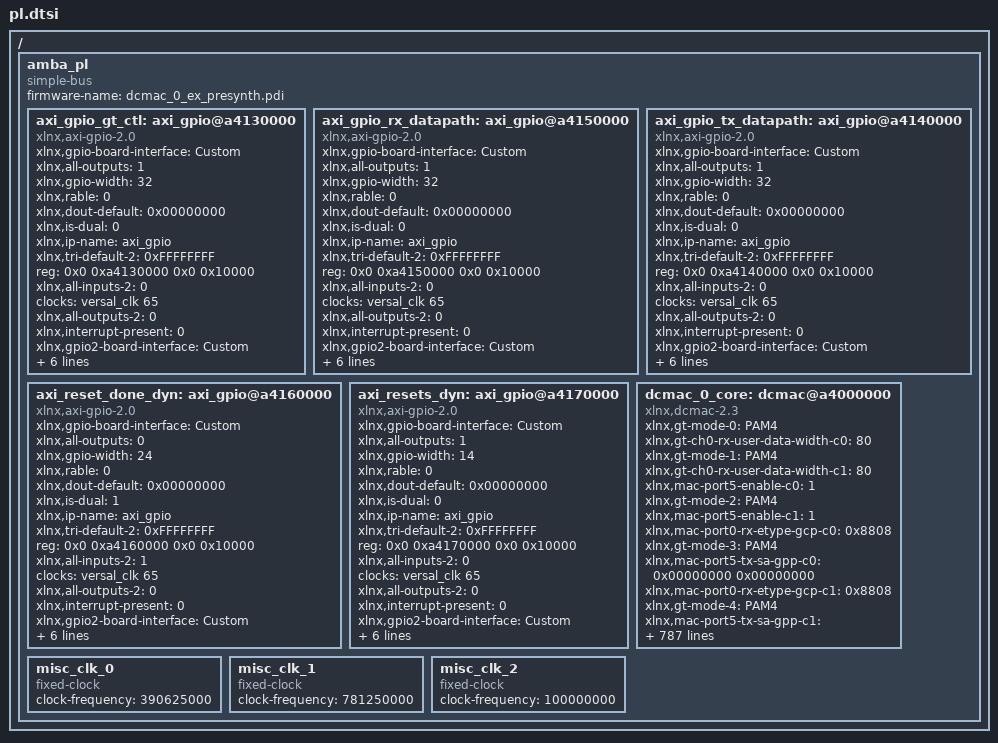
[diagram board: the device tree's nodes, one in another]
/ {
	amba_pl: amba_pl {
		ranges;
		compatible = "simple-bus";
		#address-cells = <2>;
		#size-cells = <2>;
		firmware-name = "dcmac_0_ex_presynth.pdi";
		axi_gpio_gt_ctl: axi_gpio@a4130000 {
			xlnx,gpio-board-interface = "Custom";
			compatible = "xlnx,axi-gpio-2.0" , "xlnx,xps-gpio-1.00.a";
			xlnx,all-outputs = <1>;
			xlnx,gpio-width = <32>;
			xlnx,rable = <0>;
			xlnx,dout-default = <0x00000000>;
			xlnx,is-dual = <0>;
			xlnx,ip-name = "axi_gpio";
			xlnx,tri-default-2 = <0xFFFFFFFF>;
			reg = <0x0 0xa4130000 0x0 0x10000>;
			xlnx,all-inputs-2 = <0>;
			clocks = <&versal_clk 65>;
			xlnx,all-outputs-2 = <0>;
			xlnx,interrupt-present = <0>;
			xlnx,gpio2-board-interface = "Custom";
			xlnx,edk-iptype = "PERIPHERAL";
			xlnx,dout-default-2 = <0x00000000>;
			xlnx,gpio2-width = <32>;
			status = "okay";
			clock-names = "s_axi_aclk";
			xlnx,tri-default = <0xFFFFFFFF>;
			xlnx,name = "axi_gpio_gt_ctl";
			xlnx,all-inputs = <0>;
		};
		axi_gpio_rx_datapath: axi_gpio@a4150000 {
			xlnx,gpio-board-interface = "Custom";
			compatible = "xlnx,axi-gpio-2.0" , "xlnx,xps-gpio-1.00.a";
			xlnx,all-outputs = <1>;
			xlnx,gpio-width = <32>;
			xlnx,rable = <0>;
			xlnx,dout-default = <0x00000000>;
			xlnx,is-dual = <0>;
			xlnx,ip-name = "axi_gpio";
			xlnx,tri-default-2 = <0xFFFFFFFF>;
			reg = <0x0 0xa4150000 0x0 0x10000>;
			xlnx,all-inputs-2 = <0>;
			clocks = <&versal_clk 65>;
			xlnx,all-outputs-2 = <0>;
			xlnx,interrupt-present = <0>;
			xlnx,gpio2-board-interface = "Custom";
			xlnx,edk-iptype = "PERIPHERAL";
			xlnx,dout-default-2 = <0x00000000>;
			xlnx,gpio2-width = <32>;
			status = "okay";
			clock-names = "s_axi_aclk";
			xlnx,tri-default = <0xFFFFFFFF>;
			xlnx,name = "axi_gpio_rx_datapath";
			xlnx,all-inputs = <0>;
		};
		axi_gpio_tx_datapath: axi_gpio@a4140000 {
			xlnx,gpio-board-interface = "Custom";
			compatible = "xlnx,axi-gpio-2.0" , "xlnx,xps-gpio-1.00.a";
			xlnx,all-outputs = <1>;
			xlnx,gpio-width = <32>;
			xlnx,rable = <0>;
			xlnx,dout-default = <0x00000000>;
			xlnx,is-dual = <0>;
			xlnx,ip-name = "axi_gpio";
			xlnx,tri-default-2 = <0xFFFFFFFF>;
			reg = <0x0 0xa4140000 0x0 0x10000>;
			xlnx,all-inputs-2 = <0>;
			clocks = <&versal_clk 65>;
			xlnx,all-outputs-2 = <0>;
			xlnx,interrupt-present = <0>;
			xlnx,gpio2-board-interface = "Custom";
			xlnx,edk-iptype = "PERIPHERAL";
			xlnx,dout-default-2 = <0x00000000>;
			xlnx,gpio2-width = <32>;
			status = "okay";
			clock-names = "s_axi_aclk";
			xlnx,tri-default = <0xFFFFFFFF>;
			xlnx,name = "axi_gpio_tx_datapath";
			xlnx,all-inputs = <0>;
		};
		axi_reset_done_dyn: axi_gpio@a4160000 {
			xlnx,gpio-board-interface = "Custom";
			compatible = "xlnx,axi-gpio-2.0" , "xlnx,xps-gpio-1.00.a";
			xlnx,all-outputs = <0>;
			xlnx,gpio-width = <24>;
			xlnx,rable = <0>;
			xlnx,dout-default = <0x00000000>;
			xlnx,is-dual = <1>;
			xlnx,ip-name = "axi_gpio";
			xlnx,tri-default-2 = <0xFFFFFFFF>;
			reg = <0x0 0xa4160000 0x0 0x10000>;
			xlnx,all-inputs-2 = <1>;
			clocks = <&versal_clk 65>;
			xlnx,all-outputs-2 = <0>;
			xlnx,interrupt-present = <0>;
			xlnx,gpio2-board-interface = "Custom";
			xlnx,edk-iptype = "PERIPHERAL";
			xlnx,dout-default-2 = <0x00000000>;
			xlnx,gpio2-width = <24>;
			status = "okay";
			clock-names = "s_axi_aclk";
			xlnx,tri-default = <0xFFFFFFFF>;
			xlnx,name = "axi_reset_done_dyn";
			xlnx,all-inputs = <1>;
		};
		axi_resets_dyn: axi_gpio@a4170000 {
			xlnx,gpio-board-interface = "Custom";
			compatible = "xlnx,axi-gpio-2.0" , "xlnx,xps-gpio-1.00.a";
			xlnx,all-outputs = <1>;
			xlnx,gpio-width = <14>;
			xlnx,rable = <0>;
			xlnx,dout-default = <0x00000000>;
			xlnx,is-dual = <0>;
			xlnx,ip-name = "axi_gpio";
			xlnx,tri-default-2 = <0xFFFFFFFF>;
			reg = <0x0 0xa4170000 0x0 0x10000>;
			xlnx,all-inputs-2 = <0>;
			clocks = <&versal_clk 65>;
			xlnx,all-outputs-2 = <0>;
			xlnx,interrupt-present = <0>;
			xlnx,gpio2-board-interface = "Custom";
			xlnx,edk-iptype = "PERIPHERAL";
			xlnx,dout-default-2 = <0x00000000>;
			xlnx,gpio2-width = <32>;
			status = "okay";
			clock-names = "s_axi_aclk";
			xlnx,tri-default = <0xFFFFFFFF>;
			xlnx,name = "axi_resets_dyn";
			xlnx,all-inputs = <0>;
		};
		dcmac_0_core: dcmac@a4000000 {
			xlnx,gt-mode-0 = "PAM4";
			xlnx,gt-ch0-rx-user-data-width-c0 = <80>;
			xlnx,gt-mode-1 = "PAM4";
			xlnx,gt-ch0-rx-user-data-width-c1 = <80>;
			xlnx,mac-port5-enable-c0 = <1>;
			xlnx,gt-mode-2 = "PAM4";
			xlnx,mac-port5-enable-c1 = <1>;
			xlnx,mac-port0-rx-etype-gcp-c0 = <0x8808>;
			xlnx,gt-mode-3 = "PAM4";
			xlnx,mac-port5-tx-sa-gpp-c0 = <0x00000000 0x00000000>;
			xlnx,mac-port0-rx-etype-gcp-c1 = <0x8808>;
			xlnx,gt-mode-4 = "PAM4";
			xlnx,mac-port5-tx-sa-gpp-c1 = <0x00000000 0x00000000>;
			xlnx,mac-port2-rx-etype-gcp-c0 = <0x8808>;
			xlnx,mac-port2-rx-etype-gcp-c1 = <0x8808>;
			xlnx,mac-port1-rx-flow-c0 = <0>;
			reg = <0x0 0xa4000000 0x0 0x100000>;
			xlnx,gt-ch0-tx-int-data-width-c0 = <80>;
			xlnx,mac-port4-rx-etype-gcp-c0 = <0x8808>;
			xlnx,mac-port3-tx-insert-c0 = <1>;
			xlnx,mac-port1-rx-flow-c1 = <0>;
			xlnx,gt-ch0-tx-int-data-width-c1 = <80>;
			xlnx,mac-port4-rx-etype-gcp-c1 = <0x8808>;
			xlnx,mac-port3-tx-insert-c1 = <1>;
			xlnx,mac-port2-tx-ethertype-ppp-c0 = <0x8808>;
			xlnx,mac-port2-tx-ethertype-ppp-c1 = <0x8808>;
			xlnx,gt-ch1-txprogdiv-freq-val-c0 = <0x266ac338>;
			xlnx,gt-ch1-txprogdiv-freq-val-c1 = <0x266ac338>;
			xlnx,port5-1588v2-operation-mode-c0 = "No , operation";
			xlnx,gt-ch2-rx-data-decoding-c0 = "RAW";
			xlnx,port5-1588v2-operation-mode-c1 = "No , operation";
			xlnx,oth-pcs-port0-config3-c0 = "N/A";
			xlnx,mac-port4-tx-sa-ppp-c0 = <0x00000000 0x00000000>;
			xlnx,diffclk-board-interface = "Custom";
			xlnx,gt-ch2-rx-data-decoding-c1 = "RAW";
			xlnx,oth-pcs-port0-config3-c1 = "100CAUI-4";
			xlnx,mac-port4-tx-sa-ppp-c1 = <0x00000000 0x00000000>;
			xlnx,mac-port4-rx-pause-da-ucast-c0 = <0x00000000 0x00000000>;
			xlnx,mac-port4-rx-pause-da-ucast-c1 = <0x00000000 0x00000000>;
			xlnx,mac-port0-rx-opcode-min-pcp-c0 = <0x0000>;
			xlnx,mac-port0-rx-opcode-min-pcp-c1 = <0x0000>;
			xlnx,mac-port3-preemption-c0 = <0>;
			xlnx,mac-port2-rx-opcode-max-pcp-c0 = <0xFFFF>;
			xlnx,mac-port3-preemption-c1 = <0>;
			xlnx,mac-port2-rx-opcode-max-pcp-c1 = <0xFFFF>;
			xlnx,mac-port0-tx-opcode-ppp-c0 = <0x0101>;
			xlnx,gt-ch0-tx-pll-type-c0 = "LCPLL";
			xlnx,oth-pcs-port2-config4-c0 = "N/A";
			xlnx,mac-port2-tx-ethertype-gpp-c0 = <0x8808>;
			xlnx,mac-port0-tx-opcode-ppp-c1 = <0x0101>;
			xlnx,gt-ch0-tx-pll-type-c1 = "LCPLL";
			xlnx,oth-pcs-port2-config4-c1 = "100CAUI-4";
			xlnx,mac-port4-config-c0 = "Disabled";
			xlnx,mac-port2-tx-ethertype-gpp-c1 = <0x8808>;
			xlnx,num-gt-channels-port0 = <2>;
			xlnx,mac-port4-config-c1 = "N/A";
			xlnx,num-gt-channels-port1 = <2>;
			xlnx,num-gt-channels-port2 = <2>;
			xlnx,mac-port4-tx-sa-gpp-c0 = <0x00000000 0x00000000>;
			xlnx,num-gt-channels-port3 = <2>;
			xlnx,mac-port4-tx-sa-gpp-c1 = <0x00000000 0x00000000>;
			xlnx,num-gt-channels-port4 = <0>;
			xlnx,mac-port3-rx-pause-da-mcast-c0 = <0x00000180 0xC2000001>;
			xlnx,port0-1588v2-operation-mode-c0 = "No , operation";
			xlnx,num-gt-channels-port5 = <0>;
			xlnx,mac-port3-rx-pause-da-mcast-c1 = <0x00000180 0xC2000001>;
			xlnx,mac-port2-tx-insert-c0 = <1>;
			xlnx,port2-1588v2-clocking-c0 = "Ordinary/Boundary , Clock";
			xlnx,port0-1588v2-operation-mode-c1 = "No , operation";
			xlnx,mac-port2-tx-insert-c1 = <1>;
			xlnx,mac-port2-rx-flow-c0 = <0>;
			xlnx,mac-port0-rx-opcode-min-gcp-c0 = <0x0000>;
			xlnx,name = "dcmac_0_core";
			xlnx,gt-ch2-rx-outclk-source-c0 = "RXPROGDIVCLK";
			xlnx,port2-1588v2-clocking-c1 = "Ordinary/Boundary , Clock";
			xlnx,mac-port2-rx-flow-c1 = <0>;
			xlnx,mac-port0-rx-opcode-min-gcp-c1 = <0x0000>;
			xlnx,gt-ch2-rx-outclk-source-c1 = "RXPROGDIVCLK";
			xlnx,gt-ch2-txprogdiv-freq-source-c0 = "LCPLL";
			xlnx,mac-port0-rx-etype-ppp-c0 = <0x8808>;
			xlnx,gt-ch2-txprogdiv-freq-source-c1 = "LCPLL";
			xlnx,mac-port0-rx-etype-ppp-c1 = <0x8808>;
			xlnx,mac-port3-tx-sa-ppp-c0 = <0x00000000 0x00000000>;
			xlnx,mac-port2-rx-opcode-max-gcp-c0 = <0xFFFF>;
			xlnx,mac-port2-rx-etype-ppp-c0 = <0x8808>;
			xlnx,gt-mode-dyn = "PAM4";
			xlnx,gt-drp-clk-c0 = <100>;
			xlnx,mac-port3-tx-sa-ppp-c1 = <0x00000000 0x00000000>;
			xlnx,mac-port2-rx-opcode-max-gcp-c1 = <0xFFFF>;
			xlnx,mac-port2-rx-etype-ppp-c1 = <0x8808>;
			xlnx,gt-drp-clk-c1 = <100>;
			xlnx,gt-ch2-tx-user-data-width-c0 = <80>;
			xlnx,oth-pcs-port1-config3-c0 = "N/A";
			xlnx,mac-port4-rx-etype-ppp-c0 = <0x8808>;
			xlnx,mac-port0-tx-opcode-gpp-c0 = <0x0001>;
			xlnx,gt-ch2-tx-user-data-width-c1 = <80>;
			xlnx,oth-pcs-port1-config3-c1 = "100CAUI-4";
			xlnx,mac-port5-tx-da-ppp-c0 = <0x00000180 0xC2000001>;
			xlnx,mac-port4-rx-etype-ppp-c1 = <0x8808>;
			xlnx,mac-port0-tx-opcode-gpp-c1 = <0x0001>;
			xlnx,mac-port5-tx-da-ppp-c1 = <0x00000180 0xC2000001>;
			xlnx,gt-ch3-txprogdiv-freq-enable-c0;
			xlnx,mac-port2-tx-opcode-ppp-c0 = <0x0101>;
			xlnx,gt-ch3-txprogdiv-freq-enable-c1;
			xlnx,mac-port5-rx-pause-sa-c0 = <0x00000000 0x00000000>;
			xlnx,mac-port3-tx-ethertype-ppp-c0 = <0x8808>;
			xlnx,mac-port2-tx-opcode-ppp-c1 = <0x0101>;
			xlnx,port5-1588v2-clocking-c0 = "Ordinary/Boundary , Clock";
			xlnx,mac-port5-rx-pause-sa-c1 = <0x00000000 0x00000000>;
			xlnx,mac-port3-tx-ethertype-ppp-c1 = <0x8808>;
			xlnx,gt-ch1-rx-buffer-mode-c0 = <1>;
			xlnx,port5-1588v2-clocking-c1 = "Ordinary/Boundary , Clock";
			xlnx,gt-ch1-rx-buffer-mode-c1 = <1>;
			xlnx,gt-ch1-tx-buffer-mode-c0 = <1>;
			xlnx,gt-ch3-rx-data-decoding-c0 = "RAW";
			clock-names = "rx_axi_clk" , "rx_core_clk" , "rx_flexif_clk" , "rx_macif_clk" , "s_axi_aclk" , "ts_clk" , "tx_axi_clk" , "tx_core_clk" , "tx_flexif_clk" , "tx_macif_clk";
			xlnx,mac-port1-rx-opcode-ppp-c0 = <0x0101>;
			xlnx,mac-port0-enable-c0 = <1>;
			xlnx,gt-ch1-tx-buffer-mode-c1 = <1>;
			xlnx,gt-ch3-rx-data-decoding-c1 = "RAW";
			xlnx,mac-port1-rx-opcode-ppp-c1 = <0x0101>;
			xlnx,mac-port0-enable-c1 = <1>;
			xlnx,gt-ch2-rxprogdiv-freq-source-c0 = "LCPLL";
			xlnx,gtm-group-select2-c0 = "GTM_DUAL_X0Y0";
			xlnx,gt-ch1-tx-int-data-width-c0 = <80>;
			xlnx,gt-ch2-rxprogdiv-freq-source-c1 = "LCPLL";
			xlnx,oth-pcs-port3-config4-c0 = "N/A";
			xlnx,mac-port0-rx-etype-gpp-c0 = <0x8808>;
			xlnx,gtm-group-select2-c1 = "GTM_DUAL_X0Y0";
			xlnx,ethernet-board-interface = "Custom";
			xlnx,gt-ch1-tx-int-data-width-c1 = <80>;
			xlnx,oth-pcs-port3-config4-c1 = "100CAUI-4";
			xlnx,mac-port0-rx-etype-gpp-c1 = <0x8808>;
			xlnx,mac-port3-tx-sa-gpp-c0 = <0x00000000 0x00000000>;
			xlnx,mac-port2-rx-etype-gpp-c0 = <0x8808>;
			xlnx,oth-pcs-port0-config2-c0 = "N/A";
			xlnx,mac-port3-tx-sa-gpp-c1 = <0x00000000 0x00000000>;
			xlnx,mac-port2-rx-etype-gpp-c1 = <0x8808>;
			xlnx,mac-port2-enable-time-stamping-c0 = <0>;
			xlnx,oth-pcs-port0-config2-c1 = "100CAUI-4";
			xlnx,num-gt-channels-port5-con1 = <0>;
			xlnx,mac-port4-rx-etype-gpp-c0 = <0x8808>;
			xlnx,mac-port2-enable-time-stamping-c1 = <0>;
			xlnx,num-gt-channels-port5-con2 = <0>;
			xlnx,mac-port5-tx-da-gpp-c0 = <0x00000180 0xC2000001>;
			xlnx,mac-port4-rx-etype-gpp-c1 = <0x8808>;
			xlnx,mac-port1-tx-insert-c0 = <1>;
			xlnx,gt-ch3-rxprogdiv-freq-enable-c0;
			xlnx,num-gt-channels-port5-con3 = <0>;
			xlnx,mac-port5-tx-da-gpp-c1 = <0x00000180 0xC2000001>;
			xlnx,mac-port1-tx-insert-c1 = <1>;
			xlnx,gt-ch3-rxprogdiv-freq-enable-c1;
			xlnx,phy-operating-mode-c0 = "N/A";
			xlnx,num-gt-channels-port5-con4 = <0>;
			xlnx,mac-port5-rx-pause-da-ucast-c0 = <0x00000000 0x00000000>;
			xlnx,mac-port2-tx-opcode-gpp-c0 = <0x0001>;
			xlnx,mac-port5-rx-pause-da-ucast-c1 = <0x00000000 0x00000000>;
			xlnx,mac-port3-tx-ethertype-gpp-c0 = <0x8808>;
			xlnx,mac-port3-rx-flow-c0 = <0>;
			xlnx,mac-port2-tx-opcode-gpp-c1 = <0x0001>;
			xlnx,gt-ch0-tx-line-rate-c0 = <0x9d5b34>;
			xlnx,gt-ch2-rxprogdiv-freq-val-c0 = <0x266ac338>;
			xlnx,gt-ch3-tx-refclk-frequency-c0 = <0x9502f90>;
			xlnx,num-gt-channels-port2-con1 = <0>;
			xlnx,mac-port3-tx-ethertype-gpp-c1 = <0x8808>;
			xlnx,mac-port3-rx-flow-c1 = <0>;
			xlnx,mac-port1-rx-opcode-min-pcp-c0 = <0x0000>;
			xlnx,gt-ch0-tx-line-rate-c1 = <0x9d5b34>;
			xlnx,gt-ch2-rxprogdiv-freq-val-c1 = <0x266ac338>;
			xlnx,gt-ch3-tx-refclk-frequency-c1 = <0x9502f90>;
			xlnx,num-gt-channels-port2-con2 = <0>;
			xlnx,mac-port4-tx-opcode-ppp-c0 = <0x0101>;
			xlnx,mac-port2-tx-sa-ppp-c0 = <0x00000000 0x00000000>;
			xlnx,mac-port1-rx-opcode-min-pcp-c1 = <0x0000>;
			xlnx,gt-ch2-tx-line-rate-c0 = <0x9d5b34>;
			xlnx,num-gt-channels-port2-con3 = <0>;
			xlnx,mac-port4-tx-opcode-ppp-c1 = <0x0101>;
			xlnx,mac-port2-tx-sa-ppp-c1 = <0x00000000 0x00000000>;
			xlnx,gt-ch2-tx-line-rate-c1 = <0x9d5b34>;
			xlnx,num-gt-channels-port2-con4 = <0>;
			xlnx,mac-port1-rx-opcode-gpp-c0 = <0x0001>;
			xlnx,mac-port4-tx-da-ppp-c0 = <0x00000180 0xC2000001>;
			xlnx,mac-port3-rx-opcode-max-pcp-c0 = <0xFFFF>;
			xlnx,mac-port1-rx-opcode-gpp-c1 = <0x0001>;
			xlnx,oth-pcs-port2-config3-c0 = "N/A";
			xlnx,mac-port4-tx-da-ppp-c1 = <0x00000180 0xC2000001>;
			xlnx,mac-port3-rx-opcode-max-pcp-c1 = <0xFFFF>;
			xlnx,oth-pcs-port2-config3-c1 = "100CAUI-4";
			xlnx,mac-port3-rx-opcode-ppp-c0 = <0x0101>;
			xlnx,gt-ch2-tx-refclk-frequency-c0 = <0x9502f90>;
			xlnx,mac-port3-rx-opcode-ppp-c1 = <0x0101>;
			xlnx,gt-ch2-tx-refclk-frequency-c1 = <0x9502f90>;
			xlnx,gt-ch3-rx-outclk-source-c0 = "RXPROGDIVCLK";
			xlnx,gt-ch3-rx-outclk-source-c1 = "RXPROGDIVCLK";
			xlnx,gt-ch3-tx-pll-type-c0 = "LCPLL";
			xlnx,port4-1588v2-operation-mode-c0 = "No , operation";
			xlnx,gt-ch0-tx-user-data-width-c0 = <80>;
			xlnx,gt-ch3-tx-pll-type-c1 = "LCPLL";
			xlnx,port4-1588v2-operation-mode-c1 = "No , operation";
			xlnx,gt-ch0-tx-user-data-width-c1 = <80>;
			xlnx,mac-port5-rx-strip-c0 = <0>;
			xlnx,mac-port5-rx-strip-c1 = <0>;
			xlnx,mac-port4-preemption-c0 = <0>;
			xlnx,mac-port1-rx-pause-sa-c0 = <0x00000000 0x00000000>;
			xlnx,mac-port4-rx-pause-da-mcast-c0 = <0x00000180 0xC2000001>;
			xlnx,mac-port4-preemption-c1 = <0>;
			xlnx,mac-port1-rx-pause-sa-c1 = <0x00000000 0x00000000>;
			xlnx,gt-ch1-tx-refclk-frequency-c0 = <0x9502f90>;
			xlnx,mac-port4-rx-pause-da-mcast-c1 = <0x00000180 0xC2000001>;
			xlnx,gt-ch1-tx-refclk-frequency-c1 = <0x9502f90>;
			xlnx,mac-port1-rx-opcode-min-gcp-c0 = <0x0000>;
			xlnx,oth-pcs-port4-config4-c0 = "N/A";
			xlnx,mac-port4-tx-opcode-gpp-c0 = <0x0001>;
			xlnx,mac-port2-tx-sa-gpp-c0 = <0x00000000 0x00000000>;
			xlnx,mac-port1-rx-opcode-min-gcp-c1 = <0x0000>;
			xlnx,oth-pcs-port4-config4-c1 = "100CAUI-4";
			xlnx,mac-port4-tx-opcode-gpp-c1 = <0x0001>;
			xlnx,mac-port4-tx-ethertype-ppp-c0 = <0x8808>;
			xlnx,mac-port2-tx-sa-gpp-c1 = <0x00000000 0x00000000>;
			xlnx,mac-port4-tx-ethertype-ppp-c1 = <0x8808>;
			xlnx,fec-slice5-cfg-c0 = "FEC , Disabled";
			xlnx,oth-pcs-port1-config2-c0 = "N/A";
			xlnx,mac-port4-tx-da-gpp-c0 = <0x00000180 0xC2000001>;
			xlnx,mac-port3-rx-opcode-max-gcp-c0 = <0xFFFF>;
			xlnx,mac-port0-tx-insert-c0 = <1>;
			xlnx,fec-slice5-cfg-c1 = "N/A";
			xlnx,oth-pcs-port1-config2-c1 = "100CAUI-4";
			xlnx,mac-port4-tx-da-gpp-c1 = <0x00000180 0xC2000001>;
			xlnx,mac-port3-rx-opcode-max-gcp-c1 = <0xFFFF>;
			xlnx,mac-port0-tx-insert-c1 = <1>;
			xlnx,gt-ch0-tx-refclk-frequency-c0 = <0x9502f90>;
			xlnx,mac-port3-rx-opcode-gpp-c0 = <0x0001>;
			xlnx,gt-ch0-tx-refclk-frequency-c1 = <0x9502f90>;
			xlnx,mac-port3-rx-opcode-gpp-c1 = <0x0001>;
			xlnx,mac-port2-enable-c0 = <1>;
			xlnx,mac-port2-enable-c1 = <1>;
			xlnx,gt-pipeline-stages = <0>;
			xlnx,mac-port5-rx-opcode-ppp-c0 = <0x0101>;
			xlnx,mac-port4-rx-flow-c0 = <0>;
			xlnx,mac-port1-tx-sa-ppp-c0 = <0x00000000 0x00000000>;
			xlnx,mac-port5-rx-opcode-ppp-c1 = <0x0101>;
			xlnx,mac-port4-rx-flow-c1 = <0>;
			xlnx,mac-port1-tx-sa-ppp-c1 = <0x00000000 0x00000000>;
			xlnx,gt-ch3-rx-user-data-width-c0 = <80>;
			xlnx,mac-port3-tx-da-ppp-c0 = <0x00000180 0xC2000001>;
			xlnx,gt-ch0-rx-int-data-width-c0 = <80>;
			xlnx,gt-ch3-rx-user-data-width-c1 = <80>;
			xlnx,mac-port3-tx-da-ppp-c1 = <0x00000180 0xC2000001>;
			xlnx,gt-ch0-rx-int-data-width-c1 = <80>;
			xlnx,gtm-group-select1-c0 = "GTM_DUAL_X0Y0";
			xlnx,gt-ch0-rxprogdiv-freq-val-c0 = <0x266ac338>;
			xlnx,oth-pcs-port3-config3-c0 = "N/A";
			xlnx,include-auto-neg-lt-logic-c0 = "None";
			xlnx,gtm-group-select1-c1 = "GTM_DUAL_X0Y0";
			xlnx,gt-ch0-rxprogdiv-freq-val-c1 = <0x266ac338>;
			xlnx,gt-ch1-rx-line-rate-c0 = <0x9d5b34>;
			xlnx,gt-ch1-txprogdiv-freq-source-c0 = "LCPLL";
			xlnx,oth-pcs-port3-config3-c1 = "100CAUI-4";
			xlnx,include-auto-neg-lt-logic-c1 = "None";
			xlnx,gt-ch1-rx-line-rate-c1 = <0x9d5b34>;
			xlnx,gt-ch1-txprogdiv-freq-source-c1 = "LCPLL";
			xlnx,gt-ch2-tx-int-data-width-c0 = <80>;
			xlnx,mac-port4-tx-ethertype-gpp-c0 = <0x8808>;
			xlnx,gt-ch0-rx-buffer-mode-c0 = <1>;
			xlnx,fec-slice3-cfg-c0 = "N/A";
			xlnx,gt-ch2-tx-int-data-width-c1 = <80>;
			xlnx,gt-ch3-rx-line-rate-c0 = <0x9d5b34>;
			xlnx,oth-pcs-port0-config1-c0 = "N/A";
			xlnx,mac-port4-tx-ethertype-gpp-c1 = <0x8808>;
			xlnx,gt-ch0-rx-buffer-mode-c1 = <1>;
			xlnx,fec-slice3-cfg-c1 = "N/A";
			xlnx,gt-ch3-rx-line-rate-c1 = <0x9d5b34>;
			xlnx,oth-pcs-port0-config1-c1 = "100CAUI-4";
			xlnx,gt-ch0-tx-buffer-mode-c0 = <1>;
			status = "okay";
			xlnx,gt-ch0-tx-buffer-mode-c1 = <1>;
			xlnx,num-gt-channels-con4-valid = <0>;
			xlnx,dcmac-clients-c0 = "N/A";
			xlnx,dcmac-clients-c1 = "N/A";
			xlnx,gt-ch2-txprogdiv-freq-enable-c0;
			xlnx,gt-ch2-txprogdiv-freq-enable-c1;
			xlnx,mac-port5-rx-opcode-gpp-c0 = <0x0001>;
			xlnx,mac-port1-tx-sa-gpp-c0 = <0x00000000 0x00000000>;
			xlnx,mac-port5-rx-opcode-gpp-c1 = <0x0001>;
			xlnx,mac-port1-tx-sa-gpp-c1 = <0x00000000 0x00000000>;
			xlnx,oth-pcs-port5-config4-c0 = "N/A";
			xlnx,mac-port2-rx-opcode-min-pcp-c0 = <0x0000>;
			xlnx,lane1-gt-loc-c0 = "X0Y0";
			xlnx,oth-pcs-port5-config4-c1 = "100CAUI-4";
			xlnx,mac-port4-rx-strip-c0 = <0>;
			xlnx,mac-port3-tx-da-gpp-c0 = <0x00000180 0xC2000001>;
			xlnx,mac-port2-rx-opcode-min-pcp-c1 = <0x0000>;
			xlnx,lane1-gt-loc-c1 = "X0Y0";
			xlnx,is-board-project = <1>;
			xlnx,mac-port4-rx-strip-c1 = <0>;
			xlnx,mac-port3-tx-da-gpp-c1 = <0x00000180 0xC2000001>;
			xlnx,oth-pcs-port2-config2-c0 = "N/A";
			xlnx,mac-port1-config-c0 = "N/A";
			xlnx,gt-ch1-rxprogdiv-freq-source-c0 = "LCPLL";
			xlnx,oth-pcs-port2-config2-c1 = "100CAUI-4";
			xlnx,mac-port4-rx-opcode-max-pcp-c0 = <0xFFFF>;
			xlnx,mac-port1-config-c1 = "N/A";
			xlnx,gt-ch1-rxprogdiv-freq-source-c1 = "LCPLL";
			xlnx,mac-port4-rx-opcode-max-pcp-c1 = <0xFFFF>;
			xlnx,fec-slice1-cfg-c0 = "N/A";
			xlnx,mac-port0-tx-sa-ppp-c0 = <0x00000000 0x00000000>;
			xlnx,fec-slice1-cfg-c1 = "N/A";
			xlnx,mac-port0-tx-sa-ppp-c1 = <0x00000000 0x00000000>;
			xlnx,mac-port5-rx-flow-c0 = <0>;
			xlnx,mac-port0-rx-pause-da-ucast-c0 = <0x00000000 0x00000000>;
			xlnx,edk-iptype = "PERIPHERAL";
			xlnx,mac-port5-tx-ethertype-ppp-c0 = <0x8808>;
			xlnx,mac-port5-rx-flow-c1 = <0>;
			xlnx,mac-port2-tx-da-ppp-c0 = <0x00000180 0xC2000001>;
			xlnx,mac-port0-rx-pause-da-ucast-c1 = <0x00000000 0x00000000>;
			xlnx,num-gt-channels-con3-valid = <0>;
			xlnx,mac-port5-tx-ethertype-ppp-c1 = <0x8808>;
			xlnx,mac-port2-tx-da-ppp-c1 = <0x00000180 0xC2000001>;
			xlnx,gt-ch2-rxprogdiv-freq-enable-c0;
			xlnx,port0-1588v2-clocking-c0 = "Ordinary/Boundary , Clock";
			xlnx,gt-ch2-rxprogdiv-freq-enable-c1;
			xlnx,port0-1588v2-clocking-c1 = "Ordinary/Boundary , Clock";
			xlnx,mac-port5-rx-pause-da-mcast-c0 = <0x00000180 0xC2000001>;
			xlnx,oth-pcs-port4-config3-c0 = "N/A";
			xlnx,mac-port5-rx-pause-da-mcast-c1 = <0x00000180 0xC2000001>;
			xlnx,mac-port4-rx-pause-sa-c0 = <0x00000000 0x00000000>;
			xlnx,oth-pcs-port4-config3-c1 = "100CAUI-4";
			xlnx,mac-port4-rx-pause-sa-c1 = <0x00000000 0x00000000>;
			xlnx,mac-port4-enable-c0 = <1>;
			xlnx,mac-port2-rx-opcode-min-gcp-c0 = <0x0000>;
			xlnx,gt-ch1-rx-user-data-width-c0 = <80>;
			xlnx,mac-port4-enable-c1 = <1>;
			xlnx,mac-port2-rx-opcode-min-gcp-c1 = <0x0000>;
			xlnx,mac-port1-enable-time-stamping-c0 = <0>;
			xlnx,gt-ch1-rx-user-data-width-c1 = <80>;
			xlnx,oth-pcs-port1-config1-c0 = "N/A";
			xlnx,mac-port1-enable-time-stamping-c1 = <0>;
			xlnx,oth-pcs-port1-config1-c1 = "100CAUI-4";
			xlnx,num-gt-channels-con0 = <8>;
			xlnx,enable-phase-fifo = <0>;
			xlnx,num-gt-channels-con1 = <10>;
			xlnx,mac-port4-rx-opcode-max-gcp-c0 = <0xFFFF>;
			xlnx,mac-port1-rx-etype-pcp-c0 = <0x8808>;
			xlnx,num-gt-channels-con2 = <10>;
			xlnx,mac-port5-preemption-c0 = <0>;
			xlnx,mac-port5-enable-time-stamping-c0 = <0>;
			xlnx,mac-port4-rx-opcode-max-gcp-c1 = <0xFFFF>;
			xlnx,mac-port1-rx-etype-pcp-c1 = <0x8808>;
			xlnx,num-gt-channels-con3 = <10>;
			xlnx,mac-port5-preemption-c1 = <0>;
			xlnx,mac-port5-enable-time-stamping-c1 = <0>;
			xlnx,mac-port3-rx-etype-pcp-c0 = <0x8808>;
			xlnx,mac-port0-tx-sa-gpp-c0 = <0x00000000 0x00000000>;
			xlnx,port3-1588v2-clocking-c0 = "Ordinary/Boundary , Clock";
			xlnx,num-gt-channels-con4 = <10>;
			xlnx,mac-port3-rx-etype-pcp-c1 = <0x8808>;
			xlnx,mac-port0-tx-sa-gpp-c1 = <0x00000000 0x00000000>;
			xlnx,port3-1588v2-operation-mode-c0 = "No , operation";
			xlnx,port3-1588v2-clocking-c1 = "Ordinary/Boundary , Clock";
			xlnx,mac-port5-rx-etype-pcp-c0 = <0x8808>;
			xlnx,port3-1588v2-operation-mode-c1 = "No , operation";
			xlnx,mac-port5-tx-ethertype-gpp-c0 = <0x8808>;
			xlnx,mac-port5-rx-etype-pcp-c1 = <0x8808>;
			xlnx,mac-port2-tx-da-gpp-c0 = <0x00000180 0xC2000001>;
			xlnx,gt-ch2-txprogdiv-freq-val-c0 = <0x266ac338>;
			xlnx,num-gt-channels-con2-valid = <0>;
			xlnx,mac-port5-tx-ethertype-gpp-c1 = <0x8808>;
			xlnx,mac-port2-tx-da-gpp-c1 = <0x00000180 0xC2000001>;
			xlnx,gt-ch2-txprogdiv-freq-val-c1 = <0x266ac338>;
			xlnx,gt-ch1-rx-int-data-width-c0 = <80>;
			xlnx,oth-pcs-port3-config2-c0 = "N/A";
			xlnx,gt-ch1-rx-int-data-width-c1 = <80>;
			xlnx,oth-pcs-port3-config2-c1 = "100CAUI-4";
			xlnx,mac-port0-tx-flow-c0 = <0>;
			xlnx,gt-ch0-tx-outclk-source-c0 = "TXPROGDIVCLK";
			xlnx,mac-port0-tx-flow-c1 = <0>;
			xlnx,gt-ch0-tx-outclk-source-c1 = "TXPROGDIVCLK";
			xlnx,mac-port0-preemption-c0 = <0>;
			xlnx,gt-ch3-tx-int-data-width-c0 = <80>;
			xlnx,mac-port3-rx-strip-c0 = <0>;
			xlnx,mac-port1-tx-da-ppp-c0 = <0x00000180 0xC2000001>;
			xlnx,mac-port0-preemption-c1 = <0>;
			xlnx,gt-ch3-tx-int-data-width-c1 = <80>;
			xlnx,mac-port3-rx-strip-c1 = <0>;
			xlnx,mac-port1-tx-da-ppp-c1 = <0x00000180 0xC2000001>;
			xlnx,mac-port1-rx-etype-gcp-c0 = <0x8808>;
			xlnx,mac-port1-rx-etype-gcp-c1 = <0x8808>;
			xlnx,mac-port3-rx-etype-gcp-c0 = <0x8808>;
			xlnx,mac-port3-rx-etype-gcp-c1 = <0x8808>;
			xlnx,mac-port3-config-c0 = "N/A";
			xlnx,mac-port5-rx-etype-gcp-c0 = <0x8808>;
			xlnx,mac-port3-config-c1 = "N/A";
			xlnx,gt-ch2-tx-pll-type-c0 = "LCPLL";
			xlnx,oth-pcs-port5-config3-c0 = "N/A";
			xlnx,mac-port5-rx-etype-gcp-c1 = <0x8808>;
			xlnx,gt-ch2-tx-pll-type-c1 = "LCPLL";
			xlnx,oth-pcs-port5-config3-c1 = "100CAUI-4";
			xlnx,num-gt-channels-con1-valid = <0>;
			xlnx,num-gt-channels-port4-con1 = <0>;
			xlnx,mac-port3-rx-opcode-min-pcp-c0 = <0x0000>;
			xlnx,oth-pcs-port2-config1-c0 = "N/A";
			xlnx,num-gt-channels-port4-con2 = <0>;
			xlnx,mac-port3-rx-opcode-min-pcp-c1 = <0x0000>;
			xlnx,mac-port0-rx-pause-sa-c0 = <0x00000000 0x00000000>;
			xlnx,oth-pcs-port2-config1-c1 = "100CAUI-4";
			xlnx,num-gt-channels-port4-con3 = <0>;
			xlnx,mac-port0-rx-pause-sa-c1 = <0x00000000 0x00000000>;
			xlnx,gt-ch0-tx-data-encoding-c0 = "RAW";
			xlnx,num-gt-channels-port4-con4 = <0>;
			xlnx,gt-ch0-tx-data-encoding-c1 = "RAW";
			xlnx,gt-ch0-txprogdiv-freq-source-c0 = "LCPLL";
			xlnx,mac-port5-rx-opcode-max-pcp-c0 = <0xFFFF>;
			xlnx,gt-ch0-txprogdiv-freq-source-c1 = "LCPLL";
			xlnx,num-gt-channels-port1-con1 = <0>;
			xlnx,mac-port5-rx-opcode-max-pcp-c1 = <0xFFFF>;
			compatible = "xlnx,dcmac-2.3";
			xlnx,num-gt-channels-port1-con2 = <0>;
			xlnx,mac-port1-tx-da-gpp-c0 = <0x00000180 0xC2000001>;
			xlnx,num-gt-channels-port1-con3 = <0>;
			xlnx,mac-port1-tx-da-gpp-c1 = <0x00000180 0xC2000001>;
			xlnx,num-gt-channels-port1-con4 = <0>;
			xlnx,mac-port1-rx-pause-da-ucast-c0 = <0x00000000 0x00000000>;
			xlnx,mac-port1-rx-pause-da-ucast-c1 = <0x00000000 0x00000000>;
			xlnx,gt-ch1-txprogdiv-freq-enable-c0;
			xlnx,gt-ch3-tx-user-data-width-c0 = <80>;
			xlnx,gt-ch3-tx-user-data-width-c1 = <80>;
			xlnx,gt-ch1-txprogdiv-freq-enable-c1;
			xlnx,oth-pcs-port4-config2-c0 = "N/A";
			xlnx,oth-pcs-port4-config2-c1 = "100CAUI-4";
			xlnx,mac-port1-tx-flow-c0 = <0>;
			xlnx,gt-ch0-txprogdiv-freq-val-c0 = <0x266ac338>;
			xlnx,num-gt-channels-con0-valid = <8>;
			xlnx,mac-port1-tx-flow-c1 = <0>;
			xlnx,mac-port0-tx-da-ppp-c0 = <0x00000180 0xC2000001>;
			xlnx,gt-ch0-txprogdiv-freq-val-c1 = <0x266ac338>;
			xlnx,mac-port3-rx-opcode-min-gcp-c0 = <0x0000>;
			xlnx,mac-port0-tx-da-ppp-c1 = <0x00000180 0xC2000001>;
			xlnx,mac-port3-rx-opcode-min-gcp-c1 = <0x0000>;
			xlnx,gt-ch0-rxprogdiv-freq-source-c0 = "LCPLL";
			xlnx,gt-ch0-rxprogdiv-freq-source-c1 = "LCPLL";
			xlnx,mac-port5-rx-opcode-max-gcp-c0 = <0xFFFF>;
			xlnx,mac-port5-rx-opcode-max-gcp-c1 = <0xFFFF>;
			xlnx,mac-port1-tx-opcode-ppp-c0 = <0x0101>;
			xlnx,mac-port1-tx-opcode-ppp-c1 = <0x0101>;
			xlnx,gt-ch1-tx-outclk-source-c0 = "TXPROGDIVCLK";
			xlnx,mac-port2-rx-strip-c0 = <0>;
			xlnx,gt-ch1-tx-outclk-source-c1 = "TXPROGDIVCLK";
			xlnx,mac-port2-rx-strip-c1 = <0>;
			xlnx,mac-port1-rx-etype-ppp-c0 = <0x8808>;
			xlnx,mac-port0-rx-pause-da-mcast-c0 = <0x00000180 0xC2000001>;
			xlnx,mac-port1-rx-etype-ppp-c1 = <0x8808>;
			xlnx,mac-port0-rx-pause-da-mcast-c1 = <0x00000180 0xC2000001>;
			xlnx,gt-ch1-rxprogdiv-freq-enable-c0;
			xlnx,mac-port3-rx-etype-ppp-c0 = <0x8808>;
			xlnx,mac-port0-rx-opcode-ppp-c0 = <0x0101>;
			xlnx,gt-ch1-rxprogdiv-freq-enable-c1;
			xlnx,oth-pcs-port3-config1-c0 = "N/A";
			xlnx,mac-port3-rx-etype-ppp-c1 = <0x8808>;
			xlnx,mac-port0-rx-opcode-ppp-c1 = <0x0101>;
			xlnx,oth-pcs-port3-config1-c1 = "100CAUI-4";
			xlnx,mac-port5-rx-etype-ppp-c0 = <0x8808>;
			xlnx,gt-ch2-rx-int-data-width-c0 = <80>;
			xlnx,timestamp-clk-period-ns = <4>;
			xlnx,mac-port5-rx-etype-ppp-c1 = <0x8808>;
			xlnx,gt-ch2-rx-int-data-width-c1 = <80>;
			xlnx,mac-port0-tx-da-gpp-c0 = <0x00000180 0xC2000001>;
			xlnx,mac-port5-config-c0 = "Disabled";
			xlnx,mac-port0-tx-da-gpp-c1 = <0x00000180 0xC2000001>;
			xlnx,gt-ch3-rxprogdiv-freq-val-c0 = <0x266ac338>;
			xlnx,mac-port5-config-c1 = "N/A";
			xlnx,gt-ch3-rxprogdiv-freq-val-c1 = <0x266ac338>;
			xlnx,dcmac-location-c0 = "DCMAC_X0Y0";
			xlnx,dcmac-location-c1 = "N/A";
			xlnx,mac-port1-tx-opcode-gpp-c0 = <0x0001>;
			xlnx,gt-ch1-tx-data-encoding-c0 = "RAW";
			xlnx,mac-port1-tx-opcode-gpp-c1 = <0x0001>;
			xlnx,gt-ch1-tx-data-encoding-c1 = "RAW";
			xlnx,port2-1588v2-operation-mode-c0 = "No , operation";
			xlnx,oth-pcs-port5-config2-c0 = "N/A";
			xlnx,gt-group-select-c0 = "X0Y0";
			xlnx,port2-1588v2-operation-mode-c1 = "No , operation";
			xlnx,oth-pcs-port5-config2-c1 = "100CAUI-4";
			xlnx,mac-port3-tx-opcode-ppp-c0 = <0x0101>;
			xlnx,mac-port2-tx-flow-c0 = <0>;
			xlnx,mac-port1-rx-etype-gpp-c0 = <0x8808>;
			xlnx,mac-port0-enable-time-stamping-c0 = <0>;
			xlnx,gt-group-select-c1 = "X0Y0";
			xlnx,mac-port3-tx-opcode-ppp-c1 = <0x0101>;
			xlnx,mac-port2-tx-flow-c1 = <0>;
			xlnx,mac-port1-rx-etype-gpp-c1 = <0x8808>;
			xlnx,mac-port1-preemption-c0 = <0>;
			xlnx,mac-port0-enable-time-stamping-c1 = <0>;
			xlnx,mac-port3-rx-etype-gpp-c0 = <0x8808>;
			xlnx,mac-port1-preemption-c1 = <0>;
			xlnx,mac-port0-rx-opcode-gpp-c0 = <0x0001>;
			xlnx,gt-ch1-tx-user-data-width-c0 = <80>;
			xlnx,mac-port4-rx-opcode-min-pcp-c0 = <0x0000>;
			xlnx,mac-port3-rx-etype-gpp-c1 = <0x8808>;
			xlnx,mac-port0-rx-opcode-gpp-c1 = <0x0001>;
			xlnx,gt-ch1-tx-user-data-width-c1 = <80>;
			xlnx,mac-port5-rx-etype-gpp-c0 = <0x8808>;
			xlnx,mac-port4-rx-opcode-min-pcp-c1 = <0x0000>;
			xlnx,mac-port4-enable-time-stamping-c0 = <0>;
			xlnx,mac-port5-rx-etype-gpp-c1 = <0x8808>;
			xlnx,mac-port4-enable-time-stamping-c1 = <0>;
			xlnx,mac-port2-rx-opcode-ppp-c0 = <0x0101>;
			xlnx,mac-port3-rx-pause-sa-c0 = <0x00000000 0x00000000>;
			xlnx,mac-port2-rx-opcode-ppp-c1 = <0x0101>;
			xlnx,mac-port3-rx-pause-sa-c1 = <0x00000000 0x00000000>;
			xlnx,gt-type-c0 = "GTM";
			xlnx,gt-type-c1 = "N/A";
			xlnx,gt-ch1-tx-line-rate-c0 = <0x9d5b34>;
			xlnx,gt-ch1-tx-line-rate-c1 = <0x9d5b34>;
			xlnx,gt-ch3-tx-line-rate-c0 = <0x9d5b34>;
			xlnx,mac-port2-rx-pause-da-ucast-c0 = <0x00000000 0x00000000>;
			xlnx,gt-ch3-tx-line-rate-c1 = <0x9d5b34>;
			xlnx,mac-port2-rx-pause-da-ucast-c1 = <0x00000000 0x00000000>;
			xlnx,dcmac-data-path-interface-c0 = "391MHz , Upto , 6 , Ports";
			xlnx,oth-pcs-port4-config1-c0 = "N/A";
			xlnx,mac-port1-enable-c0 = <1>;
			xlnx,dcmac-data-path-interface-c1 = "N/A";
			xlnx,oth-pcs-port4-config1-c1 = "100CAUI-4";
			xlnx,mac-port1-enable-c1 = <1>;
			xlnx,mac-port3-tx-opcode-gpp-c0 = <0x0001>;
			xlnx,mac-port1-rx-strip-c0 = <0>;
			xlnx,mac-port3-tx-opcode-gpp-c1 = <0x0001>;
			xlnx,mac-port1-rx-strip-c1 = <0>;
			xlnx,gt-ch2-tx-outclk-source-c0 = "TXPROGDIVCLK";
			xlnx,mac-port0-rx-opcode-max-pcp-c0 = <0xFFFF>;
			xlnx,gt-ch2-tx-outclk-source-c1 = "TXPROGDIVCLK";
			xlnx,mac-port5-tx-opcode-ppp-c0 = <0x0101>;
			xlnx,mac-port4-rx-opcode-min-gcp-c0 = <0x0000>;
			xlnx,mac-port0-rx-opcode-max-pcp-c1 = <0xFFFF>;
			xlnx,rable = <0>;
			xlnx,mac-port5-tx-opcode-ppp-c1 = <0x0101>;
			xlnx,mac-port4-rx-opcode-min-gcp-c1 = <0x0000>;
			xlnx,mac-port2-rx-opcode-gpp-c0 = <0x0001>;
			xlnx,gt-ref-clk-freq-c0 = <0x9502f90>;
			xlnx,ip-name = "dcmac";
			xlnx,port1-1588v2-clocking-c0 = "Ordinary/Boundary , Clock";
			xlnx,mac-port2-rx-opcode-gpp-c1 = <0x0001>;
			xlnx,mac-port0-tx-ethertype-ppp-c0 = <0x8808>;
			xlnx,gt-ref-clk-freq-c1 = <0x9502f90>;
			xlnx,port1-1588v2-clocking-c1 = "Ordinary/Boundary , Clock";
			xlnx,mac-port0-tx-ethertype-ppp-c1 = <0x8808>;
			xlnx,gt-ch1-rxprogdiv-freq-val-c0 = <0x266ac338>;
			xlnx,mac-port4-rx-opcode-ppp-c0 = <0x0101>;
			xlnx,gt-ch1-rxprogdiv-freq-val-c1 = <0x266ac338>;
			xlnx,mac-port4-rx-opcode-ppp-c1 = <0x0101>;
			xlnx,gt-ch0-rx-data-decoding-c0 = "RAW";
			xlnx,mac-port3-tx-flow-c0 = <0>;
			xlnx,gt-ch0-rx-data-decoding-c1 = "RAW";
			xlnx,mac-port3-tx-flow-c1 = <0>;
			xlnx,mac-port1-rx-pause-da-mcast-c0 = <0x00000180 0xC2000001>;
			xlnx,mac-port1-rx-pause-da-mcast-c1 = <0x00000180 0xC2000001>;
			xlnx,fast-sim-mode = <0>;
			xlnx,gt-ch0-txprogdiv-freq-enable-c0;
			xlnx,gt-ch3-rx-buffer-mode-c0 = <1>;
			xlnx,gt-ch0-txprogdiv-freq-enable-c1;
			xlnx,gt-ch3-rx-buffer-mode-c1 = <1>;
			xlnx,gt-ch3-tx-buffer-mode-c0 = <1>;
			xlnx,gt-ch1-tx-pll-type-c0 = "LCPLL";
			xlnx,gt-ch2-tx-data-encoding-c0 = "RAW";
			xlnx,gt-ch3-rx-int-data-width-c0 = <80>;
			xlnx,gt-ch3-tx-buffer-mode-c1 = <1>;
			xlnx,dcmac-mode-c0 = "Coupled , MAC+PCS";
			xlnx,gt-ch1-tx-pll-type-c1 = "LCPLL";
			xlnx,gt-ch2-tx-data-encoding-c1 = "RAW";
			xlnx,gt-ch3-rx-int-data-width-c1 = <80>;
			xlnx,port4-1588v2-clocking-c0 = "Ordinary/Boundary , Clock";
			xlnx,mac-port0-rx-opcode-max-gcp-c0 = <0xFFFF>;
			xlnx,dcmac-mode-c1 = "N/A";
			xlnx,port4-1588v2-clocking-c1 = "Ordinary/Boundary , Clock";
			xlnx,mac-port5-tx-opcode-gpp-c0 = <0x0001>;
			xlnx,mac-port0-rx-opcode-max-gcp-c1 = <0xFFFF>;
			xlnx,fec-slice4-cfg-c0 = "FEC , Disabled";
			xlnx,mac-port5-tx-opcode-gpp-c1 = <0x0001>;
			xlnx,fec-slice4-cfg-c1 = "N/A";
			xlnx,mac-port0-config-c0 = "400GAUI-8";
			xlnx,mac-port0-tx-ethertype-gpp-c0 = <0x8808>;
			xlnx,mac-port0-config-c1 = "N/A";
			xlnx,mac-port0-tx-ethertype-gpp-c1 = <0x8808>;
			xlnx,gt-ch0-rx-line-rate-c0 = <0x9d5b34>;
			xlnx,oth-pcs-port5-config1-c0 = "N/A";
			xlnx,mac-port4-rx-opcode-gpp-c0 = <0x0001>;
			xlnx,gt-ch0-rx-line-rate-c1 = <0x9d5b34>;
			xlnx,oth-pcs-port5-config1-c1 = "100CAUI-4";
			xlnx,mac-port4-rx-opcode-gpp-c1 = <0x0001>;
			xlnx,gt-ch2-rx-line-rate-c0 = <0x9d5b34>;
			xlnx,mac-port5-tx-insert-c0 = <1>;
			xlnx,gt-ch2-rx-line-rate-c1 = <0x9d5b34>;
			xlnx,mac-port5-tx-insert-c1 = <1>;
			xlnx,gt-ch0-rxprogdiv-freq-enable-c0;
			xlnx,gt-ch0-rxprogdiv-freq-enable-c1;
			xlnx,mac-port5-rx-opcode-min-pcp-c0 = <0x0000>;
			xlnx,gt-ch0-rx-outclk-source-c0 = "RXPROGDIVCLK";
			xlnx,mac-port5-rx-opcode-min-pcp-c1 = <0x0000>;
			xlnx,gt-ch0-rx-outclk-source-c1 = "RXPROGDIVCLK";
			xlnx,mac-port0-rx-strip-c0 = <0>;
			xlnx,mac-port3-enable-c0 = <1>;
			xlnx,mac-port0-rx-strip-c1 = <0>;
			xlnx,fec-slice2-cfg-c0 = "N/A";
			xlnx,mac-port3-enable-c1 = <1>;
			xlnx,fec-slice2-cfg-c1 = "N/A";
			xlnx,num-gt-channels-port3-con1 = <0>;
			xlnx,gt-ch2-rx-user-data-width-c0 = <80>;
			xlnx,gt-ch3-tx-outclk-source-c0 = "TXPROGDIVCLK";
			xlnx,num-gt-channels-port3-con2 = <0>;
			xlnx,mac-port4-tx-flow-c0 = <0>;
			xlnx,mac-port2-preemption-c0 = <0>;
			xlnx,gt-ch2-rx-user-data-width-c1 = <80>;
			xlnx,gt-ch3-tx-outclk-source-c1 = "TXPROGDIVCLK";
			xlnx,num-gt-channels-port3-con3 = <0>;
			xlnx,mac-port4-tx-flow-c1 = <0>;
			xlnx,mac-port2-preemption-c1 = <0>;
			xlnx,oth-pcs-port0-config4-c0 = "N/A";
			xlnx,num-gt-channels-port3-con4 = <0>;
			xlnx,mac-port3-rx-pause-da-ucast-c0 = <0x00000000 0x00000000>;
			xlnx,oth-pcs-port0-config4-c1 = "100CAUI-4";
			xlnx,mac-port3-rx-pause-da-ucast-c1 = <0x00000000 0x00000000>;
			xlnx,gt-ch3-rx-refclk-frequency-c0 = <0x9502f90>;
			clocks = <&misc_clk_0>, <&misc_clk_1>, <&misc_clk_2>, <&misc_clk_2>, <&misc_clk_2>, <&misc_clk_2>, <&misc_clk_0>, <&misc_clk_1>, <&misc_clk_2>, <&misc_clk_2>;
			xlnx,port1-1588v2-operation-mode-c0 = "No , operation";
			xlnx,num-gt-channels-port0-con1 = <0>;
			xlnx,mac-port1-tx-ethertype-ppp-c0 = <0x8808>;
			xlnx,gt-ch3-rx-refclk-frequency-c1 = <0x9502f90>;
			xlnx,port1-1588v2-operation-mode-c1 = "No , operation";
			xlnx,num-gt-channels-port0-con2 = <0>;
			xlnx,mac-port1-tx-ethertype-ppp-c1 = <0x8808>;
			xlnx,num-gt-channels-port0-con3 = <0>;
			xlnx,gt-ch3-txprogdiv-freq-source-c0 = "LCPLL";
			xlnx,num-gt-channels-port0-con4 = <0>;
			xlnx,gt-ch3-txprogdiv-freq-source-c1 = "LCPLL";
			xlnx,dcmac-configuration-type = "Static , Configuration";
			xlnx,gt-ch1-rx-data-decoding-c0 = "RAW";
			xlnx,mac-port1-rx-opcode-max-pcp-c0 = <0xFFFF>;
			xlnx,gt-ch3-txprogdiv-freq-val-c0 = <0x266ac338>;
			xlnx,gt-ch1-rx-data-decoding-c1 = "RAW";
			xlnx,mac-port5-rx-opcode-min-gcp-c0 = <0x0000>;
			xlnx,mac-port1-rx-opcode-max-pcp-c1 = <0xFFFF>;
			xlnx,gt-ch3-txprogdiv-freq-val-c1 = <0x266ac338>;
			xlnx,mac-port5-rx-opcode-min-gcp-c1 = <0x0000>;
			xlnx,mac-port0-rx-flow-c0 = <0>;
			xlnx,gt-ch2-rx-refclk-frequency-c0 = <0x9502f90>;
			xlnx,mac-port0-rx-flow-c1 = <0>;
			xlnx,fec-slice0-cfg-c0 = "RS(544) , CL119";
			xlnx,gt-ch2-rx-refclk-frequency-c1 = <0x9502f90>;
			xlnx,fec-slice0-cfg-c1 = "N/A";
			xlnx,mac-port4-tx-insert-c0 = <1>;
			xlnx,gt-ch3-tx-data-encoding-c0 = "RAW";
			xlnx,mac-port4-tx-insert-c1 = <1>;
			xlnx,gt-ch3-tx-data-encoding-c1 = "RAW";
			xlnx,mac-port3-enable-time-stamping-c0 = <0>;
			xlnx,mac-port2-rx-pause-da-mcast-c0 = <0x00000180 0xC2000001>;
			xlnx,mac-port0-rx-etype-pcp-c0 = <0x8808>;
			xlnx,gt-ch1-rx-refclk-frequency-c0 = <0x9502f90>;
			xlnx,mac-port5-tx-sa-ppp-c0 = <0x00000000 0x00000000>;
			xlnx,mac-port3-enable-time-stamping-c1 = <0>;
			xlnx,mac-port2-rx-pause-da-mcast-c1 = <0x00000180 0xC2000001>;
			xlnx,mac-port0-rx-etype-pcp-c1 = <0x8808>;
			xlnx,gt-ch1-rx-refclk-frequency-c1 = <0x9502f90>;
			xlnx,mac-port5-tx-sa-ppp-c1 = <0x00000000 0x00000000>;
			xlnx,mac-port2-rx-etype-pcp-c0 = <0x8808>;
			xlnx,mac-port2-config-c0 = "N/A";
			xlnx,mac-port1-tx-ethertype-gpp-c0 = <0x8808>;
			xlnx,num-gt-channels = <8>;
			xlnx,mac-port2-rx-etype-pcp-c1 = <0x8808>;
			xlnx,mac-port2-config-c1 = "N/A";
			xlnx,mac-port1-tx-ethertype-gpp-c1 = <0x8808>;
			xlnx,gt-ch3-rxprogdiv-freq-source-c0 = "LCPLL";
			xlnx,mac-port4-rx-etype-pcp-c0 = <0x8808>;
			xlnx,gt-ch3-rxprogdiv-freq-source-c1 = "LCPLL";
			xlnx,mac-port4-rx-etype-pcp-c1 = <0x8808>;
			xlnx,mac-port1-rx-opcode-max-gcp-c0 = <0xFFFF>;
			xlnx,mac-port1-rx-opcode-max-gcp-c1 = <0xFFFF>;
			xlnx,gt-mode-c0 = "Custom";
			xlnx,gt-ch0-rx-refclk-frequency-c0 = <0x9502f90>;
			xlnx,gt-ch2-rx-buffer-mode-c0 = <1>;
			xlnx,mac-port5-tx-flow-c0 = <0>;
			xlnx,gt-mode-c1 = "Custom";
			xlnx,gt-ch0-rx-refclk-frequency-c1 = <0x9502f90>;
			xlnx,gt-ch2-rx-buffer-mode-c1 = <1>;
			xlnx,mac-port5-tx-flow-c1 = <0>;
			xlnx,gt-ch2-tx-buffer-mode-c0 = <1>;
			xlnx,oth-pcs-port1-config4-c0 = "N/A";
			xlnx,mac-port2-rx-pause-sa-c0 = <0x00000000 0x00000000>;
			xlnx,gt-ch1-rx-outclk-source-c0 = "RXPROGDIVCLK";
			xlnx,gt-ch2-tx-buffer-mode-c1 = <1>;
			xlnx,oth-pcs-port1-config4-c1 = "100CAUI-4";
			xlnx,mac-port2-rx-pause-sa-c1 = <0x00000000 0x00000000>;
			xlnx,gt-ch1-rx-outclk-source-c1 = "RXPROGDIVCLK";
		};
		misc_clk_0: misc_clk_0 {
			compatible = "fixed-clock";
			clock-frequency = <390625000>;
			#clock-cells = <0>;
		};
		misc_clk_1: misc_clk_1 {
			compatible = "fixed-clock";
			clock-frequency = <781250000>;
			#clock-cells = <0>;
		};
		misc_clk_2: misc_clk_2 {
			compatible = "fixed-clock";
			clock-frequency = <100000000>;
			#clock-cells = <0>;
		};
	};
};
